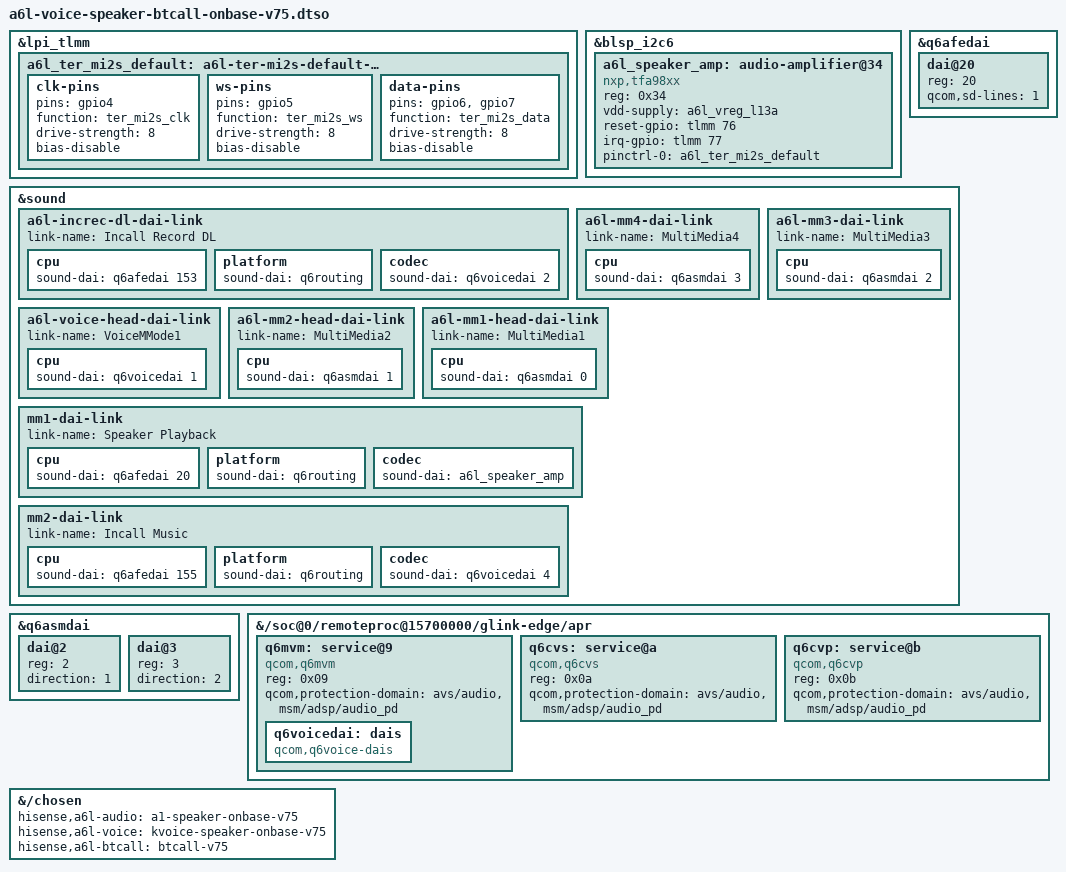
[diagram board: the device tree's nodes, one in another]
// SPDX-License-Identifier: GPL-2.0-only
// btcall (29 Sep 2026), never booted: a6l-voice-speaker-onbase-v75.dtso + the two front ends and three back ends of the
// cellular-call-to-Bluetooth bridge (docs/android-bt-audio-20260929.md, docs/btcall-kernel-20260929.md). Use INSTEAD of
// a6l-voice-speaker-onbase-v75.dtso, and ONLY with the q6voice SERIES module set (kvoice/a6l-btcall-incall-v75.patch:
// q6afe pseudo ports INCALL_RECORD_RX/TX = 153/154 (AFE 0x8003/0x8004), VOICE_PLAYBACK_TX = 155 (0x8005), q6voice-dai
// incall DAIs 2/3/4, LPASS_MAX_PORT 156). The audio4 modules reject cpu ids >= 153 (card probe fails = no audio).
// Selected by A6L_AUDIO_SET=series in tools/build-rom-v2-dt.sh; the default ROM DT keeps a6l-voice-speaker-onbase-v75.
// Merged link order (fdtoverlay PREPENDS new children, new heads are written in REVERSE; tools/check-voice-dt-links.py):
//   0 MultiMedia1 (pcmC0D0, HAL)       1 MultiMedia2              2 VoiceMMode1 (pcmC0D2, a6l-q6voiced)
//   3 MultiMedia3 (pcmC0D3c: btcall downlink = persist.vendor.a6l.btcall.dl_pcm=3)
//   4 MultiMedia4 (pcmC0D4p: btcall uplink   = persist.vendor.a6l.btcall.ul_pcm=4)
//   5 Incall Record DL (BE: q6afedai 153 + q6voicedai 2)   6 Speaker Playback (old mm1 node)
//   7 Incall Music (BE: q6afedai 155 + q6voicedai 4, old mm2 node)   8 Internal MI2S Playback   9 Internal MI2S Capture
// Routes (set by a6l-q6voiced bridge mode): 'MultiMedia3 Mixer INCALL_RECORD_RX', 'VOICE_PLAYBACK_TX Audio Mixer MultiMedia4'.
// Numeric ids on purpose: the DT build includes the unpatched baseline dt-bindings.
/dts-v1/;
/plugin/;

&lpi_tlmm {
    a6l_ter_mi2s_default: a6l-ter-mi2s-default-state {
        clk-pins { pins = "gpio4"; function = "ter_mi2s_clk"; drive-strength = <8>; bias-disable; };
        ws-pins { pins = "gpio5"; function = "ter_mi2s_ws"; drive-strength = <8>; bias-disable; };
        data-pins { pins = "gpio6", "gpio7"; function = "ter_mi2s_data"; drive-strength = <8>; bias-disable; };
    };
};

&blsp_i2c6 {
    #address-cells = <1>;
    #size-cells = <0>;
    status = "okay";
    a6l_speaker_amp: audio-amplifier@34 {
        compatible = "nxp,tfa98xx";
        reg = <0x34>;
        vdd-supply = <&a6l_vreg_l13a>;
        reset-gpio = <&tlmm 76 0>;
        irq-gpio = <&tlmm 77 0>;
        pinctrl-names = "default";
        pinctrl-0 = <&a6l_ter_mi2s_default>;
        #sound-dai-cells = <0>;
    };
};

&q6afedai {
    #address-cells = <1>;
    #size-cells = <0>;
    dai@20 { reg = <20>; qcom,sd-lines = <1>; };      /* TERTIARY_MI2S_RX: stock rx-lines 0x2 = SD1 (gpio7) */
};

&sound {
    /* new heads, REVERSED: the last written ends up link 0 */
    a6l-increc-dl-dai-link {                                                   /* ends up link 5 (BE) */
        link-name = "Incall Record DL";
        cpu { sound-dai = <&q6afedai 153>; };          /* INCALL_RECORD_RX = AFE 0x8003 */
        platform { sound-dai = <&q6routing>; };
        codec { sound-dai = <&q6voicedai 2>; };       /* VOICEMMODE1_INCALL_REC_DL: VSS_IRECORD rx tap */
    };
    a6l-mm4-dai-link { link-name = "MultiMedia4"; cpu { sound-dai = <&q6asmdai 3>; }; };   /* link 4, playback only */
    a6l-mm3-dai-link { link-name = "MultiMedia3"; cpu { sound-dai = <&q6asmdai 2>; }; };   /* link 3, capture only */
    a6l-voice-head-dai-link { link-name = "VoiceMMode1"; cpu { sound-dai = <&q6voicedai 1>; }; };   /* link 2 */
    a6l-mm2-head-dai-link { link-name = "MultiMedia2"; cpu { sound-dai = <&q6asmdai 1>; }; };  /* link 1 */
    a6l-mm1-head-dai-link { link-name = "MultiMedia1"; cpu { sound-dai = <&q6asmdai 0>; }; };  /* link 0 */
    mm1-dai-link {                                                              /* existing node, link 6 */
        link-name = "Speaker Playback";
        cpu { sound-dai = <&q6afedai 20>; };
        platform { sound-dai = <&q6routing>; };
        codec { sound-dai = <&a6l_speaker_amp>; };
    };
    mm2-dai-link {                                                              /* existing node, link 7 */
        link-name = "Incall Music";
        cpu { sound-dai = <&q6afedai 155>; };          /* VOICE_PLAYBACK_TX = AFE 0x8005 */
        platform { sound-dai = <&q6routing>; };
        codec { sound-dai = <&q6voicedai 4>; };       /* VOICEMMODE1_INCALL_MUSIC: VSS_IPLAYBACK */
    };
};

&q6asmdai {
    #address-cells = <1>;
    #size-cells = <0>;
    dai@2 { reg = <2>; direction = <1>; };            /* MultiMedia3: Q6ASM_DAI_TX (capture only) */
    dai@3 { reg = <3>; direction = <2>; };            /* MultiMedia4: Q6ASM_DAI_RX (playback only) */
};
/ {
    /* CVD services on the ADSP APR bus (same PD as q6afe/q6asm/q6adm in sdm630.dtsi). APR_SVC_ADSP_MVM/CVS/CVP = 9/0xa/0xb */
    fragment@80 {
        target-path = "/soc@0/remoteproc@15700000/glink-edge/apr";
        __overlay__ {
            #address-cells = <1>;
            #size-cells = <0>;
            q6mvm: service@9 {
                compatible = "qcom,q6mvm";
                reg = <0x09>;
                qcom,protection-domain = "avs/audio", "msm/adsp/audio_pd";
                q6voicedai: dais {
                    compatible = "qcom,q6voice-dais";
                    #sound-dai-cells = <1>;     /* <&q6voicedai 1> = VOICEMMODE1 (index == id: CS_VOICE 0, VOICEMMODE1 1) */
                    /* no qcom,cvd-v2.3 / qcom,cvd-v2.2: q6voice asks MVM (VSS_IVERSION_CMD_GET); q6voice.cvd_mode= overrides */
                };
            };
            q6cvs: service@a {
                compatible = "qcom,q6cvs";
                reg = <0x0a>;
                qcom,protection-domain = "avs/audio", "msm/adsp/audio_pd";
            };
            q6cvp: service@b {
                compatible = "qcom,q6cvp";
                reg = <0x0b>;
                qcom,protection-domain = "avs/audio", "msm/adsp/audio_pd";
            };
        };
    };
    fragment@91 { target-path = "/chosen"; __overlay__ { hisense,a6l-audio = "a1-speaker-onbase-v75"; hisense,a6l-voice = "kvoice-speaker-onbase-v75"; hisense,a6l-btcall = "btcall-v75"; }; };
};
